# ddr32ss_EMIF_CTLCFG_0F308000h register map
Vendor: Texas Instruments
Registers are 32-bit, read-write, reset 0x0 unless marked. A register's access mark holds for its fields unless they carry their own. Offsets are as the file gives them; [hi:lo] are bit positions; lines under a group give offsets from that group; {n}, {i} and the like mark numbered series.

## emif_ctlcfg (part 6 of 13)
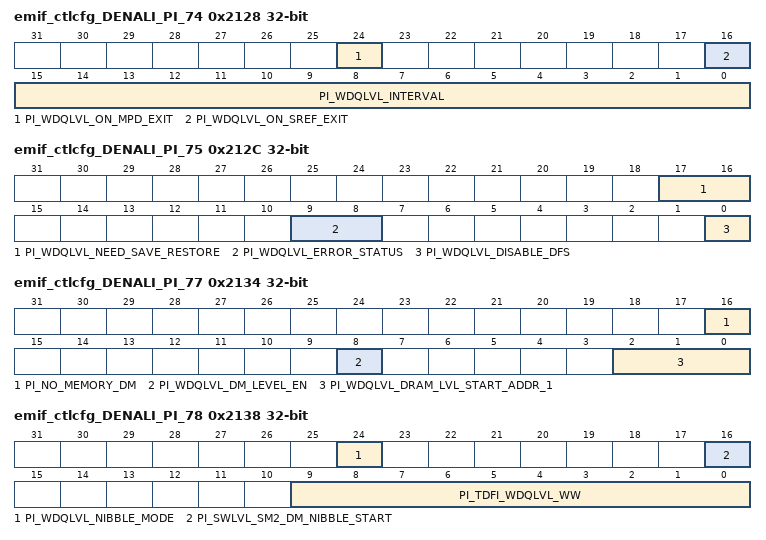
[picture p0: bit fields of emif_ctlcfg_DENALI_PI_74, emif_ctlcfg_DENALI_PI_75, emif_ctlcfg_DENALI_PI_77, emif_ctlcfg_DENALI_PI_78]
0x2128 emif_ctlcfg_DENALI_PI_74
  [24] PI_WDQLVL_ON_MPD_EXIT — Issue a write DQ training command on maximum power saving mode exit. Reset Source: ctl_amod_g_rst_n
  [16] PI_WDQLVL_ON_SREF_EXIT — Issue a write DQ training command on self-refresh exit. Reset Source: ctl_amod_g_rst_n
  [15:0] PI_WDQLVL_INTERVAL — Sets the maximum number of long count sequences allowed between automatic write DQ training operations. Reset Source: ctl_amod_g_rst_n
0x212C emif_ctlcfg_DENALI_PI_75 access per field
  [17:16] PI_WDQLVL_NEED_SAVE_RESTORE rw — Enables the use of functional DRAM address space for write DQ training, 1 = enable, not for LPDDR4. Reset Source: ctl_amod_g_rst_n
  [9:8] PI_WDQLVL_ERROR_STATUS ro — Holds the error associated with the write dq level error interrupt. Bit [0] set indicates a PI_TDFI_WDQLVL_MAX parameter violation and bit [1] set indicates a PI_TDFI_WDQLVL_RESP parameter violation. READ-ONLY. Reset Source: ctl_amod_g_rst_n
  [0] PI_WDQLVL_DISABLE_DFS rw — Disable automatic write DQ training on freq change. Set to 1 to disable. Reset Source: ctl_amod_g_rst_n
0x2130 emif_ctlcfg_DENALI_PI_76
  [31:0] PI_WDQLVL_DRAM_LVL_START_ADDR_0 — Start address of WDQ leveling, not for LPDDR4. Reset Source: ctl_amod_g_rst_n
0x2134 emif_ctlcfg_DENALI_PI_77
  [16] PI_NO_MEMORY_DM — Defines if the attached memory supports the Data Mask function, 1 = not supported. Reset Source: ctl_amod_g_rst_n
  [8] PI_WDQLVL_DM_LEVEL_EN — Enable for write DM training as part of the write DQ training, not for LPDDR4. Reset Source: ctl_amod_g_rst_n
  [2:0] PI_WDQLVL_DRAM_LVL_START_ADDR_1 — Start address of WDQ leveling, not for LPDDR4. Reset Source: ctl_amod_g_rst_n
0x2138 emif_ctlcfg_DENALI_PI_78 access per field
  [24] PI_WDQLVL_NIBBLE_MODE rw — WDQ Training Nibble mode indication. When set to 1, nibble mode is enabled, and the training timing is doubled. Reset Source: ctl_amod_g_rst_n
  [16] PI_SWLVL_SM2_DM_NIBBLE_START wo — Start command for stage 2, when in the process of DM leveling or nibble mode. WRITE-ONLY Reset Source: ctl_amod_g_rst_n
  [9:0] PI_TDFI_WDQLVL_WW rw — Minimum number of DFI clocks to be inserted between write commands during the DM portion of write DQ training. Reset Source: ctl_amod_g_rst_n
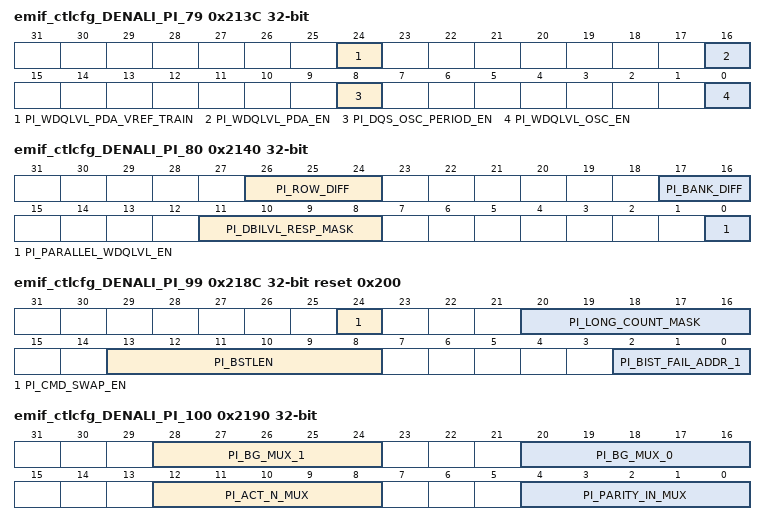
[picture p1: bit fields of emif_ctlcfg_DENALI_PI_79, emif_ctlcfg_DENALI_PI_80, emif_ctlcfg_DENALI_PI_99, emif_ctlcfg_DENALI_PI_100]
0x213C emif_ctlcfg_DENALI_PI_79
  [24] PI_WDQLVL_PDA_VREF_TRAIN — Enable for the use of PDA to set the VREF during write DQ training, 1 = enabled. Reset Source: ctl_amod_g_rst_n
  [16] PI_WDQLVL_PDA_EN — Enable for the use of write DQ training for PDA mode, 1 = enabled. Reset Source: ctl_amod_g_rst_n
  [8] PI_DQS_OSC_PERIOD_EN — Enable for DQS oscillator triggered periodic write DQ training, 1 = enabled. Reset Source: ctl_amod_g_rst_n
  [0] PI_WDQLVL_OSC_EN — Enable for DQS oscillator triggered write DQ training, 1 = enabled. Reset Source: ctl_amod_g_rst_n
0x2140 emif_ctlcfg_DENALI_PI_80
  [26:24] PI_ROW_DIFF — Difference between number of address pins available and number being used. Reset Source: ctl_amod_g_rst_n
  [17:16] PI_BANK_DIFF — Difference between number of bank pins available and number being used. Reset Source: ctl_amod_g_rst_n
  [11:8] PI_DBILVL_RESP_MASK — Mask for the dfi_rdlvl_resp signal during read dbi training. Reset Source: ctl_amod_g_rst_n
  [0] PI_PARALLEL_WDQLVL_EN — Enable per rank parallel Write DQ training for LPDDR4, 1 = enabled. Reset Source: ctl_amod_g_rst_n
0x2144 emif_ctlcfg_DENALI_PI_81
  [4:0] PI_TCCD — DRAM CAS-to-CAS value in cycles. Reset Source: ctl_amod_g_rst_n
{0x2000+4i} emif_ctlcfg_DENALI_PI_{i} access not given reset not defined (i=82..86)
0x215C emif_ctlcfg_DENALI_PI_87 ro
  [29:0] PI_INT_STATUS — Status of interrupt features in the PI. READ-ONLY Reset Source: ctl_amod_g_rst_n
0x2160 emif_ctlcfg_DENALI_PI_88 wo
  [28:0] PI_INT_ACK — Clear the corresponding interrupt bit of the PI_INT_STATUS parameter. WRITE-ONLY Reset Source: ctl_amod_g_rst_n
0x2164 emif_ctlcfg_DENALI_PI_89
  [29:0] PI_INT_MASK — Mask for PI_int signals from the PI_INT_STATUS parameter. Reset Source: ctl_amod_g_rst_n
{0x2000+4i} emif_ctlcfg_DENALI_PI_{i} ro (i=90..93)
  [31:0] PI_BIST_EXP_DATA_{i-90} — Expected data on BIST error. READ-ONLY Reset Source: ctl_amod_g_rst_n
{0x2000+4i} emif_ctlcfg_DENALI_PI_{i} ro (i=94..97)
  [31:0] PI_BIST_FAIL_DATA_{i-94} — Actual data on BIST error. READ-ONLY Reset Source: ctl_amod_g_rst_n
0x2188 emif_ctlcfg_DENALI_PI_98 ro
  [31:0] PI_BIST_FAIL_ADDR_0 — The burst aligned address of BIST error. READ-ONLY Reset Source: ctl_amod_g_rst_n
0x218C emif_ctlcfg_DENALI_PI_99 access per field reset 0x200
  [24] PI_CMD_SWAP_EN rw — Command pin swap function enable Reset Source: ctl_amod_g_rst_n
  [20:16] PI_LONG_COUNT_MASK rw — Reduces the length of the long counter from 1024 cycles. Reset Source: ctl_amod_g_rst_n
  [13:8] PI_BSTLEN rw — Encoded burst length sent to DRAMs during initialization. Reset Source: ctl_amod_g_rst_n
  [2:0] PI_BIST_FAIL_ADDR_1 ro — The burst aligned address of BIST error. READ-ONLY Reset Source: ctl_amod_g_rst_n
0x2190 emif_ctlcfg_DENALI_PI_100
  [28:24] PI_BG_MUX_1 — Command pin BG_1 mux selector Reset Source: ctl_amod_g_rst_n
  [20:16] PI_BG_MUX_0 — Command pin BG_0 mux selector Reset Source: ctl_amod_g_rst_n
  [12:8] PI_ACT_N_MUX — Command pin ACT_N mux selector Reset Source: ctl_amod_g_rst_n
  [4:0] PI_PARITY_IN_MUX — Command pin parity mux selector Reset Source: ctl_amod_g_rst_n
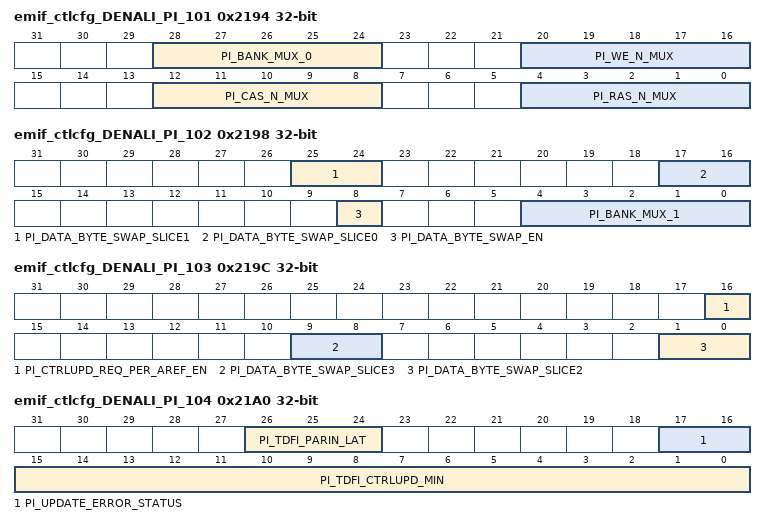
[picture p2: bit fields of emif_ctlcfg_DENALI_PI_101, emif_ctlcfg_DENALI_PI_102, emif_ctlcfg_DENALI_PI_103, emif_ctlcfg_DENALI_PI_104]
0x2194 emif_ctlcfg_DENALI_PI_101
  [28:24] PI_BANK_MUX_0 — Command pin BANK_0 mux selector Reset Source: ctl_amod_g_rst_n
  [20:16] PI_WE_N_MUX — Command pin WE_N mux selector Reset Source: ctl_amod_g_rst_n
  [12:8] PI_CAS_N_MUX — Command pin CAS_N mux selector Reset Source: ctl_amod_g_rst_n
  [4:0] PI_RAS_N_MUX — Command pin RAS_N mux selector Reset Source: ctl_amod_g_rst_n
0x2198 emif_ctlcfg_DENALI_PI_102
  [25:24] PI_DATA_BYTE_SWAP_SLICE1 — DATA pin 1 mux selector Reset Source: ctl_amod_g_rst_n
  [17:16] PI_DATA_BYTE_SWAP_SLICE0 — DATA pin 0 mux selector Reset Source: ctl_amod_g_rst_n
  [8] PI_DATA_BYTE_SWAP_EN — DATA pin swap function enable Reset Source: ctl_amod_g_rst_n
  [4:0] PI_BANK_MUX_1 — Command pin BANK_1 mux selector Reset Source: ctl_amod_g_rst_n
0x219C emif_ctlcfg_DENALI_PI_103
  [16] PI_CTRLUPD_REQ_PER_AREF_EN — Enable an automatic PI initiated update [dfi_ctrlupd_req] after every refresh. Set to 1 to enable. Reset Source: ctl_amod_g_rst_n
  [9:8] PI_DATA_BYTE_SWAP_SLICE3 — DATA pin 3 mux selector Reset Source: ctl_amod_g_rst_n
  [1:0] PI_DATA_BYTE_SWAP_SLICE2 — DATA pin 2 mux selector Reset Source: ctl_amod_g_rst_n
0x21A0 emif_ctlcfg_DENALI_PI_104 access per field
  [26:24] PI_TDFI_PARIN_LAT rw — Defines the DFI tPARIN_LAT timing parameter [in DFI PHY clocks], the maximum cycles between a DFI command and a dfi_parity_in signal assertion. Reset Source: ctl_amod_g_rst_n
  [17:16] PI_UPDATE_ERROR_STATUS ro — Identifies the source of any DFI PI-initiated update errors. Value of 1 indicates a timing violation of the associated timing parameter. Bit 1-0: ctrlupd_max_error, ctrlupd_interval_error. Bit 6-2: reserved. READ-ONLY Reset Source: ctl_amod_g_rst_n
  [15:0] PI_TDFI_CTRLUPD_MIN rw — Reports the DFI tCTRLUPD_MIN timing parameter [in DFI clocks], the minimum cycles that dfi_ctrlupd_req must be asserted. Reset Source: ctl_amod_g_rst_n
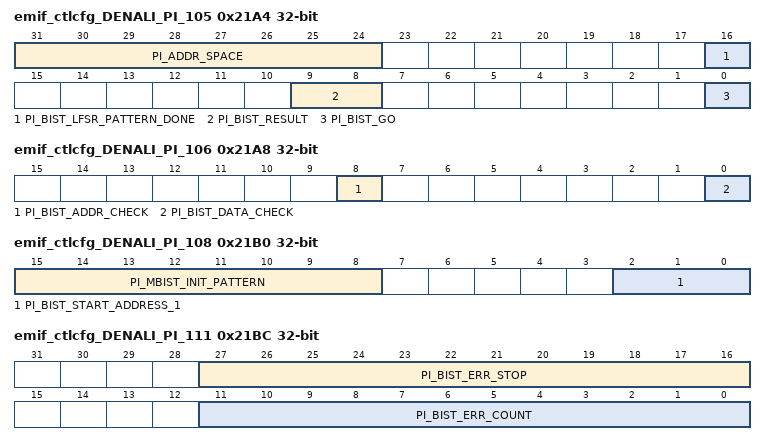
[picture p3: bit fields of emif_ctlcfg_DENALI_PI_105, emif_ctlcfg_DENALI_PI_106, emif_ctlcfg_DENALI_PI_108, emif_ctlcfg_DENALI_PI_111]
0x21A4 emif_ctlcfg_DENALI_PI_105 access per field
  [31:24] PI_ADDR_SPACE rw — Sets the number of address bits to check during BIST operation. The end address of BIST is start_address+[1 shifted up by PI_ADDR_SPACE]-1. The end address should not beyond the actual memory address range. Reset Source: ctl_amod_g_rst_n
  [16] PI_BIST_LFSR_PATTERN_DONE ro — BIST operation lfsr pattern, data pattern 1'b0 means the data is useful,1'b1 means next pattern sequence can ingore. READ-ONLY Reset Source: ctl_amod_g_rst_n
  [9:8] PI_BIST_RESULT ro — BIST operation status [pass/fail]. Bit [0] indicates data check status and bit [1] indicates address check status. Value of 1 is a passing result. READ-ONLY Reset Source: ctl_amod_g_rst_n
  [0] PI_BIST_GO rw — Initiate a BIST operation. Set to 1 to trigger. Reset Source: ctl_amod_g_rst_n
0x21A8 emif_ctlcfg_DENALI_PI_106
  [8] PI_BIST_ADDR_CHECK — Enable address checking with BIST operation. Set to 1 to enable. Reset Source: ctl_amod_g_rst_n
  [0] PI_BIST_DATA_CHECK — Enable data checking with BIST operation. Set to 1 to enable. Reset Source: ctl_amod_g_rst_n
0x21AC emif_ctlcfg_DENALI_PI_107
  [31:0] PI_BIST_START_ADDRESS_0 — Start BIST checking at this address. Reset Source: ctl_amod_g_rst_n
0x21B0 emif_ctlcfg_DENALI_PI_108
  [15:8] PI_MBIST_INIT_PATTERN — PI mbist data check, random lfsr pattern mode init pattern seed. Reset Source: ctl_amod_g_rst_n
  [2:0] PI_BIST_START_ADDRESS_1 — Start BIST checking at this address. Reset Source: ctl_amod_g_rst_n
0x21B4 emif_ctlcfg_DENALI_PI_109
  [31:0] PI_BIST_DATA_MASK_0 — Mask applied to data for BIST error checking. Bit [0] controls memory data path bit [0], bit [1] controls memory data path bit [1], etc. The mask range is the data transfer size in each memory clock cycle [The data on a rising edge and a failing edge]. Set each bit to 1 to mask. Reset Source: ctl_amod_g_rst_n
0x21B8 emif_ctlcfg_DENALI_PI_110
  [31:0] PI_BIST_DATA_MASK_1 — Mask applied to data for BIST error checking. Bit [0] controls memory data path bit [0], bit [1] controls memory data path bit [1], etc. The mask range is the data transfer size in each memory clock cycle [The data on a rising edge and a failing edge]. Set each bit to 1 to mask. Reset Source: ctl_amod_g_rst_n
0x21BC emif_ctlcfg_DENALI_PI_111 access per field
  [27:16] PI_BIST_ERR_STOP rw — Defines the maximum number of error occurrences allowed prior to quitting when the BIST_TEST_MODE parameter is set to 1, 2 or 3. A value of 0 will allow the test to run to completion. Reset Source: ctl_amod_g_rst_n
  [11:0] PI_BIST_ERR_COUNT ro — Indicates the number of BIST errors found when the BIST_TEST_MODE parameter is set to 1, 2 or 3. READ-ONLY Reset Source: ctl_amod_g_rst_n
0x21C0 emif_ctlcfg_DENALI_PI_112
  [31:0] PI_BIST_ADDR_MASK_0_0 — Defines an address to be masked during the BIST operation.. Reset Source: ctl_amod_g_rst_n
0x21C4 emif_ctlcfg_DENALI_PI_113
  [3:0] PI_BIST_ADDR_MASK_0_1 — Defines an address to be masked during the BIST operation.. Reset Source: ctl_amod_g_rst_n
0x21C8 emif_ctlcfg_DENALI_PI_114
  [31:0] PI_BIST_ADDR_MASK_1_0 — Defines an address to be masked during the BIST operation.. Reset Source: ctl_amod_g_rst_n
0x21CC emif_ctlcfg_DENALI_PI_115
  [3:0] PI_BIST_ADDR_MASK_1_1 — Defines an address to be masked during the BIST operation.. Reset Source: ctl_amod_g_rst_n
0x21D0 emif_ctlcfg_DENALI_PI_116
  [31:0] PI_BIST_ADDR_MASK_2_0 — Defines an address to be masked during the BIST operation.. Reset Source: ctl_amod_g_rst_n
0x21D4 emif_ctlcfg_DENALI_PI_117
  [3:0] PI_BIST_ADDR_MASK_2_1 — Defines an address to be masked during the BIST operation.. Reset Source: ctl_amod_g_rst_n
0x21D8 emif_ctlcfg_DENALI_PI_118
  [31:0] PI_BIST_ADDR_MASK_3_0 — Defines an address to be masked during the BIST operation.. Reset Source: ctl_amod_g_rst_n
0x21DC emif_ctlcfg_DENALI_PI_119
  [3:0] PI_BIST_ADDR_MASK_3_1 — Defines an address to be masked during the BIST operation.. Reset Source: ctl_amod_g_rst_n
0x21E0 emif_ctlcfg_DENALI_PI_120
  [31:0] PI_BIST_ADDR_MASK_4_0 — Defines an address to be masked during the BIST operation.. Reset Source: ctl_amod_g_rst_n
0x21E4 emif_ctlcfg_DENALI_PI_121
  [3:0] PI_BIST_ADDR_MASK_4_1 — Defines an address to be masked during the BIST operation.. Reset Source: ctl_amod_g_rst_n
0x21E8 emif_ctlcfg_DENALI_PI_122
  [31:0] PI_BIST_ADDR_MASK_5_0 — Defines an address to be masked during the BIST operation.. Reset Source: ctl_amod_g_rst_n
0x21EC emif_ctlcfg_DENALI_PI_123
  [3:0] PI_BIST_ADDR_MASK_5_1 — Defines an address to be masked during the BIST operation.. Reset Source: ctl_amod_g_rst_n
0x21F0 emif_ctlcfg_DENALI_PI_124
  [31:0] PI_BIST_ADDR_MASK_6_0 — Defines an address to be masked during the BIST operation.. Reset Source: ctl_amod_g_rst_n
0x21F4 emif_ctlcfg_DENALI_PI_125
  [3:0] PI_BIST_ADDR_MASK_6_1 — Defines an address to be masked during the BIST operation.. Reset Source: ctl_amod_g_rst_n
0x21F8 emif_ctlcfg_DENALI_PI_126
  [31:0] PI_BIST_ADDR_MASK_7_0 — Defines an address to be masked during the BIST operation.. Reset Source: ctl_amod_g_rst_n
0x21FC emif_ctlcfg_DENALI_PI_127
  [3:0] PI_BIST_ADDR_MASK_7_1 — Defines an address to be masked during the BIST operation.. Reset Source: ctl_amod_g_rst_n
0x2200 emif_ctlcfg_DENALI_PI_128
  [31:0] PI_BIST_ADDR_MASK_8_0 — Defines an address to be masked during the BIST operation.. Reset Source: ctl_amod_g_rst_n
0x2204 emif_ctlcfg_DENALI_PI_129
  [3:0] PI_BIST_ADDR_MASK_8_1 — Defines an address to be masked during the BIST operation.. Reset Source: ctl_amod_g_rst_n
0x2208 emif_ctlcfg_DENALI_PI_130
  [31:0] PI_BIST_ADDR_MASK_9_0 — Defines an address to be masked during the BIST operation.. Reset Source: ctl_amod_g_rst_n
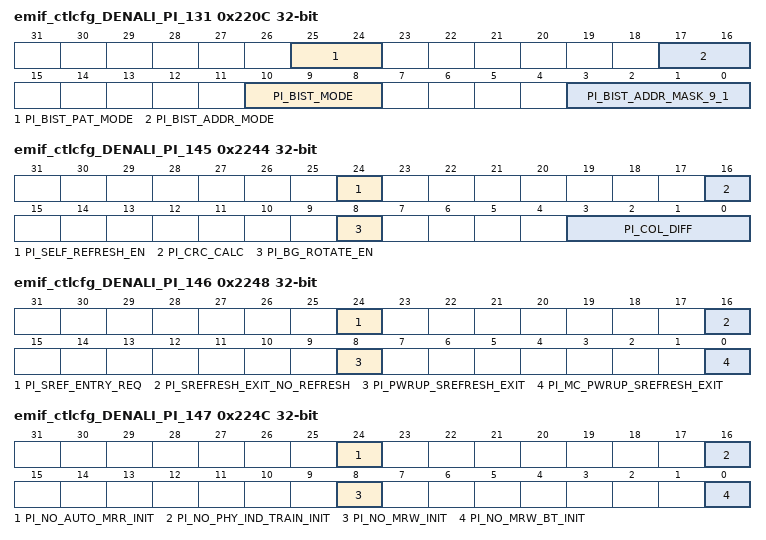
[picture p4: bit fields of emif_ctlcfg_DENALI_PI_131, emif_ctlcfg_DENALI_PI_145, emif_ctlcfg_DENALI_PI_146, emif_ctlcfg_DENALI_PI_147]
0x220C emif_ctlcfg_DENALI_PI_131
  [25:24] PI_BIST_PAT_MODE — Sets the pattern mode of BIST. 'b00 indicates using built-in pattern. 'b01 indicates checkerboard pattern, each data transfer inverts the last data transfer based on the built-in pattern. 'b10 indicates using both user pattern and built-in pattern. 'b11 indicates using pi lfsr random pattern. Reset Source: ctl_amod_g_rst_n
  [17:16] PI_BIST_ADDR_MODE — Sets the address traversing order of BIST. 'b00 indicates fast column order [burst-column-bank-row-rank]. 'b01 indicates fast row order [burst-row-column-bank-rank]. 'b10 indicates fast bank order [burst-bank-column-row-rank]. Reset Source: ctl_amod_g_rst_n
  [10:8] PI_BIST_MODE — Sets the BIST data checking mode. 'b00 indicates MOVI13N mode. 'b01 indicates March C mode. 'b10 indicates GALPAT mode. 'b11 indicates PRBS mode. 'b100 indicates programmable March data check mode. Reset Source: ctl_amod_g_rst_n
  [3:0] PI_BIST_ADDR_MASK_9_1 — Defines an address to be masked during the BIST operation.. Reset Source: ctl_amod_g_rst_n
{0x2000+4i} emif_ctlcfg_DENALI_PI_{i} (i=132..135)
  [31:0] PI_BIST_USER_PAT_{i-132} — Sets the user-specified pattern of BIST. Reset Source: ctl_amod_g_rst_n
0x2220 emif_ctlcfg_DENALI_PI_136
  [6:0] PI_BIST_PAT_NUM — Sets the max used pattern number of BIST from a total of 8 built-in patterns. Ex. set to 3, The BIST would use pattern 1, 2 and 3. Reset Source: ctl_amod_g_rst_n
{0x2000+4i} emif_ctlcfg_DENALI_PI_{i} (i=137..144)
  [29:0] PI_BIST_STAGE_{i-137} — Sets the programmable algorithm of each stage X when pi_bist_mmode = 'h4. Reset Source: ctl_amod_g_rst_n
0x2244 emif_ctlcfg_DENALI_PI_145
  [24] PI_SELF_REFRESH_EN — Control for PI to enable self refresh mode. Set to 1 to enable. Reset Source: ctl_amod_g_rst_n
  [16] PI_CRC_CALC — Defines where CRC is performed; set to 1 for PI responsibility or clear to 0 for PHY responsibility. Reset Source: ctl_amod_g_rst_n
  [8] PI_BG_ROTATE_EN — Enable bank group rotation. Set to 1 to enable. Reset Source: ctl_amod_g_rst_n
  [3:0] PI_COL_DIFF — Difference between number of column pins available and number being used. Reset Source: ctl_amod_g_rst_n
0x2248 emif_ctlcfg_DENALI_PI_146 access per field
  [24] PI_SREF_ENTRY_REQ wo — In PI power up data retention, PI can issued sref entry command. WRITE-ONLY Reset Source: ctl_amod_g_rst_n
  [16] PI_SREFRESH_EXIT_NO_REFRESH rw — Disables the automatic refresh request associated with self-refresh exit. Set to 1 to disable. Reset Source: ctl_amod_g_rst_n
  [8] PI_PWRUP_SREFRESH_EXIT rw — PI control powerup via self-refresh instead of full memory initialization. Set to 1 to enable. Reset Source: ctl_amod_g_rst_n
  [0] PI_MC_PWRUP_SREFRESH_EXIT rw — It indicates MC control powerup via self-refresh instead of full memory initialization. Set to 1 to enable. Reset Source: ctl_amod_g_rst_n
0x224C emif_ctlcfg_DENALI_PI_147
  [24] PI_NO_AUTO_MRR_INIT — Disable MRR commands during initialization. Set to 1 to disable. Reset Source: ctl_amod_g_rst_n
  [16] PI_NO_PHY_IND_TRAIN_INIT — Disable PHY Independent Training during initialization. Set to 1 to disable. Reset Source: ctl_amod_g_rst_n
  [8] PI_NO_MRW_INIT — Disable MRW commands after training during initialization. Set to 1 to disable. Reset Source: ctl_amod_g_rst_n
  [0] PI_NO_MRW_BT_INIT — Disable MRW commands before training during initialization. Set to 1 to disable. Reset Source: ctl_amod_g_rst_n
0x2250 emif_ctlcfg_DENALI_PI_148
  [31:0] PI_TRST_PWRON — Duration of memory reset during power-on initialization. Reset Source: ctl_amod_g_rst_n
0x2254 emif_ctlcfg_DENALI_PI_149
  [31:0] PI_CKE_INACTIVE — Number of cycles after reset before CKE will be active. Reset Source: ctl_amod_g_rst_n
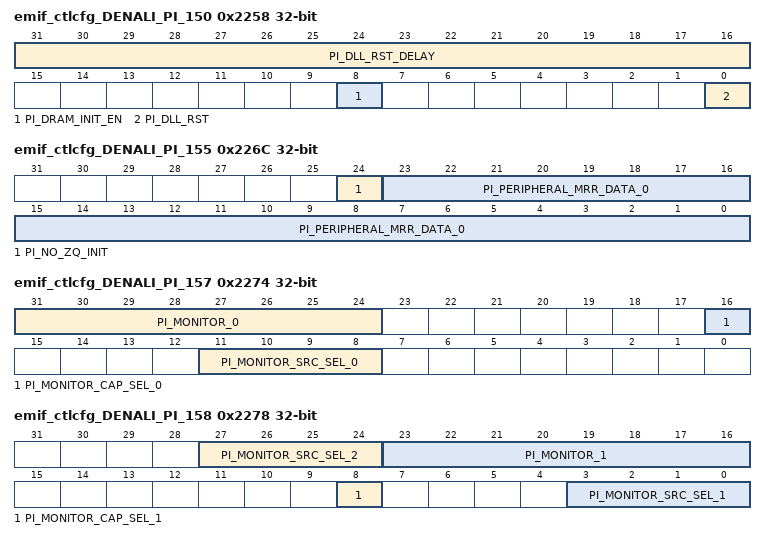
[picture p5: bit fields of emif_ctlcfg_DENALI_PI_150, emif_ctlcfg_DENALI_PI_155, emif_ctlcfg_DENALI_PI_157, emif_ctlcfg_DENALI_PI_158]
0x2258 emif_ctlcfg_DENALI_PI_150
  [31:16] PI_DLL_RST_DELAY — Minimum cycles required for DLL reset signal dll_rst_n to be held. Reset Source: ctl_amod_g_rst_n
  [8] PI_DRAM_INIT_EN — Control for the initialization of DRAM by the PI. Reset Source: ctl_amod_g_rst_n
  [0] PI_DLL_RST — Enables use of the DLL reset [dll_rst_n]. Reset Source: ctl_amod_g_rst_n
0x225C emif_ctlcfg_DENALI_PI_151
  [7:0] PI_DLL_RST_ADJ_DLY — Minimum cycles after setting master delay in DLL until the DLL reset signal dll_rst_n may be asserted. Reset Source: ctl_amod_g_rst_n
0x2260 emif_ctlcfg_DENALI_PI_152
  [25:0] PI_WRITE_MODEREG — Write memory mode register data to the DRAMs. Bits [7:0] define the memory mode register number if bit [23] is set, bits [15:8] define the chip select if bit [24] is clear, bits [23:16] define which memory mode register/s to write, bit [24] defines whether all chip selects will be written, and bit [25] triggers the write. Reset Source: ctl_amod_g_rst_n
0x2264 emif_ctlcfg_DENALI_PI_153 ro
  [7:0] PI_MRW_STATUS — Write memory mode register status. Bit [0] set indicates a WRITE_MODEREG parameter programming error. Bit [1] set indicates a PASR error. Bit [2] is Reserved. Bit [3] set indicates a self refresh or deep power down error. Bit [4] set indicates that a write to MR3 or MR11 was attempted [write_modereg bit [25] was asserted with bit [17] set, or bit [23] was asserted with bits [7:0] defining MR3 or MR11] during tZQCAL after a ZQ calibration start command. READ-ONLY Reset Source: ctl_amod_g_rst_n
0x2268 emif_ctlcfg_DENALI_PI_154
  [16:0] PI_READ_MODEREG — Read the specified memory mode register from specified chip when start bit set. Bits [7:0] define the memory mode register and bits [15:8] define the chip select. Set bit [16] to 1 to trigger. Reset Source: ctl_amod_g_rst_n
0x226C emif_ctlcfg_DENALI_PI_155 access per field
  [24] PI_NO_ZQ_INIT rw — Disable ZQ operations during initialization. Set to 1 to disable. Reset Source: ctl_amod_g_rst_n
  [23:0] PI_PERIPHERAL_MRR_DATA_0 ro — Data and chip returned from memory mode register read requested by the READ_MODEREG parameter, Bits [15:0] define MRR data, [23:16] define the chip select. READ-ONLY Reset Source: ctl_amod_g_rst_n
0x2270 emif_ctlcfg_DENALI_PI_156 ro
  [16] PI_ZQ_REQ_PENDING — Indicates that a ZQ command is currently in progress or waiting to run. When this is asserted, no writes to ZQ_REQ should occur. READ-ONLY Reset Source: ctl_amod_g_rst_n
0x2274 emif_ctlcfg_DENALI_PI_157 access per field
  [31:24] PI_MONITOR_0 ro — Monitor register 0. READ-ONLY. Reset Source: ctl_amod_g_rst_n
  [16] PI_MONITOR_CAP_SEL_0 rw — Selection of captures for pi_monitor_0. Reset Source: ctl_amod_g_rst_n
  [11:8] PI_MONITOR_SRC_SEL_0 rw — Selection of sources for pi_monitor_0. Reset Source: ctl_amod_g_rst_n
0x2278 emif_ctlcfg_DENALI_PI_158 access per field
  [27:24] PI_MONITOR_SRC_SEL_2 rw — Selection of sources for pi_monitor_2. Reset Source: ctl_amod_g_rst_n
  [23:16] PI_MONITOR_1 ro — Monitor register 1. READ-ONLY. Reset Source: ctl_amod_g_rst_n
  [8] PI_MONITOR_CAP_SEL_1 rw — Selection of captures for pi_monitor_1. Reset Source: ctl_amod_g_rst_n
  [3:0] PI_MONITOR_SRC_SEL_1 rw — Selection of sources for pi_monitor_1. Reset Source: ctl_amod_g_rst_n
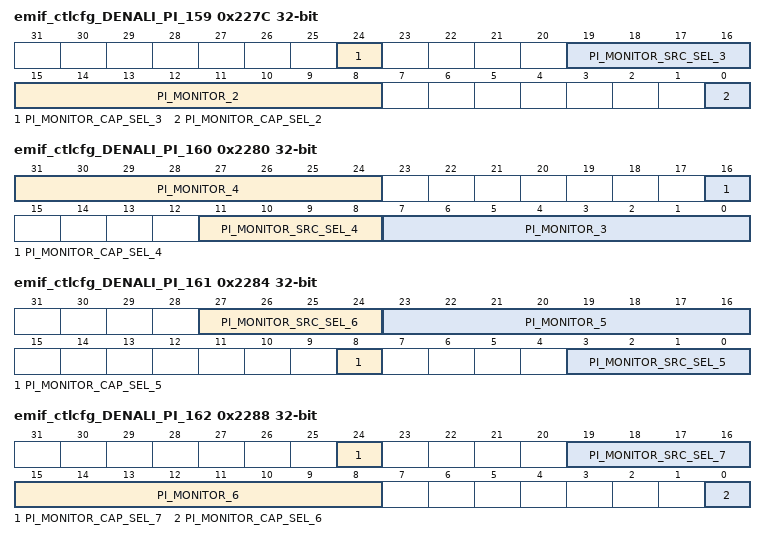
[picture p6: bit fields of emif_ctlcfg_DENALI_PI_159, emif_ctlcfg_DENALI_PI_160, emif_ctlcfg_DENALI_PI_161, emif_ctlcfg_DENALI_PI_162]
0x227C emif_ctlcfg_DENALI_PI_159 access per field
  [24] PI_MONITOR_CAP_SEL_3 rw — Selection of captures for pi_monitor_3. Reset Source: ctl_amod_g_rst_n
  [19:16] PI_MONITOR_SRC_SEL_3 rw — Selection of sources for pi_monitor_3. Reset Source: ctl_amod_g_rst_n
  [15:8] PI_MONITOR_2 ro — Monitor register 2. READ-ONLY. Reset Source: ctl_amod_g_rst_n
  [0] PI_MONITOR_CAP_SEL_2 rw — Selection of captures for pi_monitor_2. Reset Source: ctl_amod_g_rst_n
0x2280 emif_ctlcfg_DENALI_PI_160 access per field
  [31:24] PI_MONITOR_4 ro — Monitor register 4. READ-ONLY. Reset Source: ctl_amod_g_rst_n
  [16] PI_MONITOR_CAP_SEL_4 rw — Selection of captures for pi_monitor_4. Reset Source: ctl_amod_g_rst_n
  [11:8] PI_MONITOR_SRC_SEL_4 rw — Selection of sources for pi_monitor_4. Reset Source: ctl_amod_g_rst_n
  [7:0] PI_MONITOR_3 ro — Monitor register 3. READ-ONLY. Reset Source: ctl_amod_g_rst_n
0x2284 emif_ctlcfg_DENALI_PI_161 access per field
  [27:24] PI_MONITOR_SRC_SEL_6 rw — Selection of sources for pi_monitor_6. Reset Source: ctl_amod_g_rst_n
  [23:16] PI_MONITOR_5 ro — Monitor register 5. READ-ONLY. Reset Source: ctl_amod_g_rst_n
  [8] PI_MONITOR_CAP_SEL_5 rw — Selection of captures for pi_monitor_5. Reset Source: ctl_amod_g_rst_n
  [3:0] PI_MONITOR_SRC_SEL_5 rw — Selection of sources for pi_monitor_5. Reset Source: ctl_amod_g_rst_n
0x2288 emif_ctlcfg_DENALI_PI_162 access per field
  [24] PI_MONITOR_CAP_SEL_7 rw — Selection of captures for pi_monitor_7. Reset Source: ctl_amod_g_rst_n
  [19:16] PI_MONITOR_SRC_SEL_7 rw — Selection of sources for pi_monitor_7. Reset Source: ctl_amod_g_rst_n
  [15:8] PI_MONITOR_6 ro — Monitor register 6. READ-ONLY. Reset Source: ctl_amod_g_rst_n
  [0] PI_MONITOR_CAP_SEL_6 rw — Selection of captures for pi_monitor_6. Reset Source: ctl_amod_g_rst_n
0x228C emif_ctlcfg_DENALI_PI_163 ro
  [7:0] PI_MONITOR_7 — Monitor register 7. READ-ONLY. Reset Source: ctl_amod_g_rst_n
0x2290 emif_ctlcfg_DENALI_PI_164 wo
  [7:0] PI_MONITOR_STROBE — Strobe the pi_monitor once. Every bit corresponds respectively with a pi_monitor. WRITE-ONLY Reset Source: ctl_amod_g_rst_n
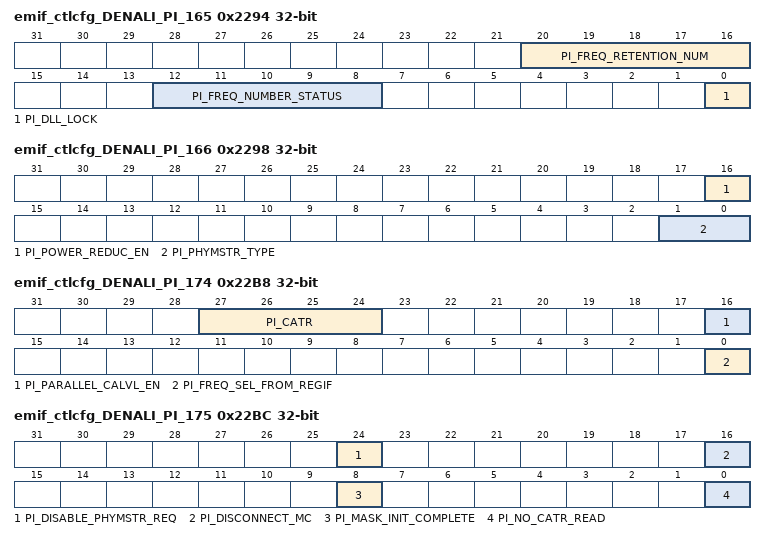
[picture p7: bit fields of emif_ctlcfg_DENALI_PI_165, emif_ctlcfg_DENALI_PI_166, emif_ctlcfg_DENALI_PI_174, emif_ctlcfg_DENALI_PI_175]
0x2294 emif_ctlcfg_DENALI_PI_165 access per field
  [20:16] PI_FREQ_RETENTION_NUM rw — Monitor active freq number in PI for data_retention Reset Source: ctl_amod_g_rst_n
  [12:8] PI_FREQ_NUMBER_STATUS ro — Monitor active freq number in PI. READ-ONLY. Reset Source: ctl_amod_g_rst_n
  [0] PI_DLL_LOCK ro — Monitor dfi_init_complete from PHY. READ-ONLY. Reset Source: ctl_amod_g_rst_n
0x2298 emif_ctlcfg_DENALI_PI_166
  [16] PI_POWER_REDUC_EN — PI Power reduction enable, 1 = enabled. Reset Source: ctl_amod_g_rst_n
  [1:0] PI_PHYMSTR_TYPE — Defines how the controller should set the state of DRAM before turning control of the DFI bus over to the PI. Reset Source: ctl_amod_g_rst_n
{0x2000+4i} emif_ctlcfg_DENALI_PI_{i} access not given reset not defined (i=167..170)
0x22AC emif_ctlcfg_DENALI_PI_171
  [23:16] PI_WRLVL_MAX_STROBE_PEND — Defines the maximum number of wrlvl_strobes that be accumulated before an AREF is prevented from being generated. Reset Source: ctl_amod_g_rst_n
0x22B0 emif_ctlcfg_DENALI_PI_172
  [8:0] PI_TREFBW_THR — Threshold value to control the AREF command interval. When the number of pending AREF is over this value, the interval is expanded to be tREF/8. Reset Source: ctl_amod_g_rst_n
0x22B4 emif_ctlcfg_DENALI_PI_173
  [4:0] PI_FREQ_CHANGE_REG_COPY — In non-DFI 4.0 mode, contains the frequency copy value. Reset Source: ctl_amod_g_rst_n
0x22B8 emif_ctlcfg_DENALI_PI_174
  [27:24] PI_CATR — It indicates LP4 DRAM CA terminition ON/OFF state. Each bit corresponds to each chip select. 1:ON 0:OFF. This parameter is active when PI_NO_CATR_READ==1. When PI_NO_CATR_READ==0, this param is inactive Reset Source: ctl_amod_g_rst_n
  [16] PI_PARALLEL_CALVL_EN — Enable parallel channel CA training for LPDDR4. 1: All the channels in one rank do CA Training in parallel. 0: Each channel does CA Training in sequence Reset Source: ctl_amod_g_rst_n
  [0] PI_FREQ_SEL_FROM_REGIF — In non-DFI 4.0 mode, user select the frequency copies from pi_freq_change_reg_copy. Reset Source: ctl_amod_g_rst_n
0x22BC emif_ctlcfg_DENALI_PI_175
  [24] PI_DISABLE_PHYMSTR_REQ — PI mask dfi_phymstr_req to the controller and get dfi bus without dfi_phymstr_ack, 1: disconnect Reset Source: ctl_amod_g_rst_n
  [16] PI_DISCONNECT_MC — PI disconnects the controller from the PHY, 1: disconnect Reset Source: ctl_amod_g_rst_n
  [8] PI_MASK_INIT_COMPLETE — Enable the masking of the dfi_init_complete signal back to the controller, 1: mask. Reset Source: ctl_amod_g_rst_n
  [0] PI_NO_CATR_READ — Defines how the LPDDR4 termination status is determined. 1: PI use PI_CATR to get DRAM CA Termination status. 0: PI reads DRAM MR0.OP7 to get DRAM CA Termination status. Reset Source: ctl_amod_g_rst_n
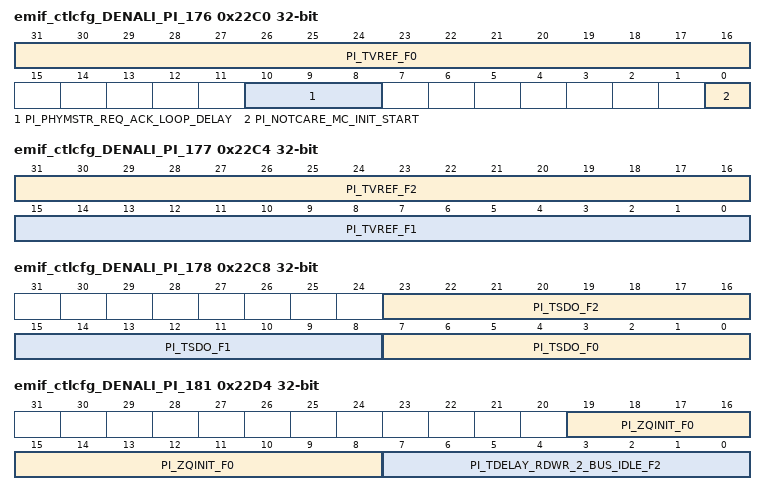
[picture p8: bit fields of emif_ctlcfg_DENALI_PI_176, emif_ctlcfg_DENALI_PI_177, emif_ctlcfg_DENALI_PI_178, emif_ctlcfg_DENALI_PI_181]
0x22C0 emif_ctlcfg_DENALI_PI_176
  [31:16] PI_TVREF_F0 — Defines the number of cycles that the PI should wait before issuing the next command after a VREF training MRW command for frequency set 0. Reset Source: ctl_amod_g_rst_n
  [10:8] PI_PHYMSTR_REQ_ACK_LOOP_DELAY — The delay between phymstr_req and inner phymstr_ack when PI_DISABLE_PHYMSTR_REQ set 1 Reset Source: ctl_amod_g_rst_n
  [0] PI_NOTCARE_MC_INIT_START — Defines whether PI waits for the controller to initiate dfi_init_start before PI memory initialization, 1: wait for dfi_init_start Reset Source: ctl_amod_g_rst_n
0x22C4 emif_ctlcfg_DENALI_PI_177
  [31:16] PI_TVREF_F2 — Defines the number of cycles that the PI should wait before issuing the next command after a VREF training MRW command for frequency set 2. Reset Source: ctl_amod_g_rst_n
  [15:0] PI_TVREF_F1 — Defines the number of cycles that the PI should wait before issuing the next command after a VREF training MRW command for frequency set 1. Reset Source: ctl_amod_g_rst_n
0x22C8 emif_ctlcfg_DENALI_PI_178
  [23:16] PI_TSDO_F2 — The delay from the read preamble training MRS command to the data strobe drive out for frequency set 2, in PI clocks Reset Source: ctl_amod_g_rst_n
  [15:8] PI_TSDO_F1 — The delay from the read preamble training MRS command to the data strobe drive out for frequency set 1, in PI clocks Reset Source: ctl_amod_g_rst_n
  [7:0] PI_TSDO_F0 — The delay from the read preamble training MRS command to the data strobe drive out for frequency set 0, in PI clocks Reset Source: ctl_amod_g_rst_n
0x22CC emif_ctlcfg_DENALI_PI_179
  [7:0] PI_TDELAY_RDWR_2_BUS_IDLE_F0 — The delay from read or write to bus idle for frequency set 0. Recommend setting is: delay time from read command issued to last read data received. Reset Source: ctl_amod_g_rst_n
0x22D0 emif_ctlcfg_DENALI_PI_180
  [7:0] PI_TDELAY_RDWR_2_BUS_IDLE_F1 — The delay from read or write to bus idle for frequency set 1. Recommend setting is: delay time from read command issued to last read data received. Reset Source: ctl_amod_g_rst_n
0x22D4 emif_ctlcfg_DENALI_PI_181
  [19:8] PI_ZQINIT_F0 — Number of cycles needed for a ZQINIT command for frequency set 0. Reset Source: ctl_amod_g_rst_n
  [7:0] PI_TDELAY_RDWR_2_BUS_IDLE_F2 — The delay from read or write to bus idle for frequency set 2. Recommend setting is: delay time from read command issued to last read data received. Reset Source: ctl_amod_g_rst_n
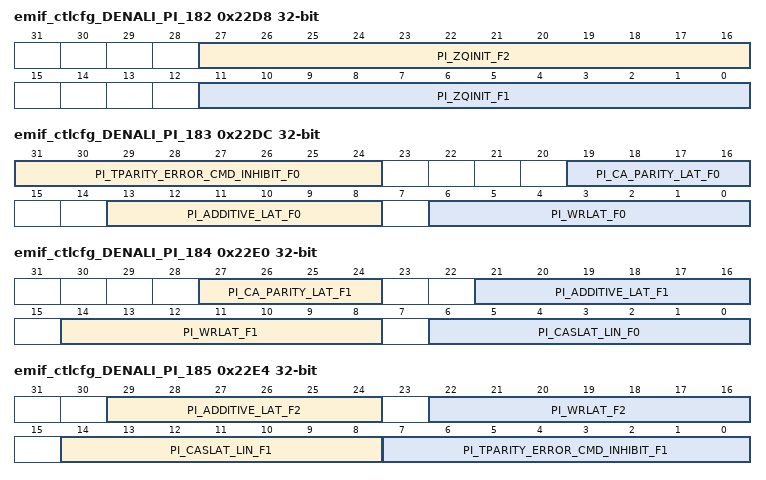
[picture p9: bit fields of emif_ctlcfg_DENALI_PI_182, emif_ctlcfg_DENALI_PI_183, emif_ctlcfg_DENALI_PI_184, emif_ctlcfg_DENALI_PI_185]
0x22D8 emif_ctlcfg_DENALI_PI_182
  [27:16] PI_ZQINIT_F2 — Number of cycles needed for a ZQINIT command for frequency set 2. Reset Source: ctl_amod_g_rst_n
  [11:0] PI_ZQINIT_F1 — Number of cycles needed for a ZQINIT command for frequency set 1. Reset Source: ctl_amod_g_rst_n
0x22DC emif_ctlcfg_DENALI_PI_183
  [31:24] PI_TPARITY_ERROR_CMD_INHIBIT_F0 — Defines the window after the PI receives a parity error during which DRAM commands will not execute for frequency set 0. Reset Source: ctl_amod_g_rst_n
  [19:16] PI_CA_PARITY_LAT_F0 — DRAM CA parity latency value in cycles for frequency set 0. Reset Source: ctl_amod_g_rst_n
  [13:8] PI_ADDITIVE_LAT_F0 — DRAM additive latency value in cycles for frequency set 0. Reset Source: ctl_amod_g_rst_n
  [6:0] PI_WRLAT_F0 — DRAM WRLAT value in cycles for frequency set 0. Reset Source: ctl_amod_g_rst_n
0x22E0 emif_ctlcfg_DENALI_PI_184
  [27:24] PI_CA_PARITY_LAT_F1 — DRAM CA parity latency value in cycles for frequency set 1. Reset Source: ctl_amod_g_rst_n
  [21:16] PI_ADDITIVE_LAT_F1 — DRAM additive latency value in cycles for frequency set 1. Reset Source: ctl_amod_g_rst_n
  [14:8] PI_WRLAT_F1 — DRAM WRLAT value in cycles for frequency set 1. Reset Source: ctl_amod_g_rst_n
  [6:0] PI_CASLAT_LIN_F0 — Sets latency from read command sent to data received from/to controller for frequency set 0. Bit [0] is half-cycle increment and the upper bits define memory CAS latency for the controller. Reset Source: ctl_amod_g_rst_n
0x22E4 emif_ctlcfg_DENALI_PI_185
  [29:24] PI_ADDITIVE_LAT_F2 — DRAM additive latency value in cycles for frequency set 2. Reset Source: ctl_amod_g_rst_n
  [22:16] PI_WRLAT_F2 — DRAM WRLAT value in cycles for frequency set 2. Reset Source: ctl_amod_g_rst_n
  [14:8] PI_CASLAT_LIN_F1 — Sets latency from read command sent to data received from/to controller for frequency set 1. Bit [0] is half-cycle increment and the upper bits define memory CAS latency for the controller. Reset Source: ctl_amod_g_rst_n
  [7:0] PI_TPARITY_ERROR_CMD_INHIBIT_F1 — Defines the window after the PI receives a parity error during which DRAM commands will not execute for frequency set 1. Reset Source: ctl_amod_g_rst_n
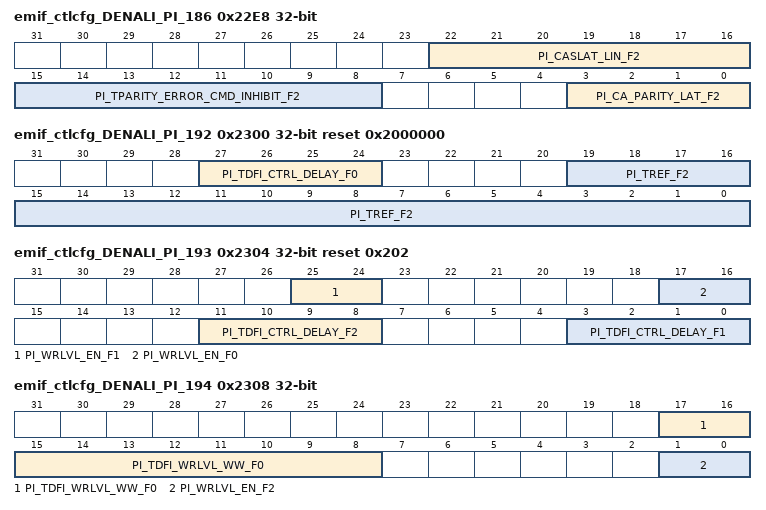
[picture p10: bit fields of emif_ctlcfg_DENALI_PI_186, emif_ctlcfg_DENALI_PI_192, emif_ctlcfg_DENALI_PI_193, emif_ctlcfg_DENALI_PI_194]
0x22E8 emif_ctlcfg_DENALI_PI_186
  [22:16] PI_CASLAT_LIN_F2 — Sets latency from read command sent to data received from/to controller for frequency set 2. Bit [0] is half-cycle increment and the upper bits define memory CAS latency for the controller. Reset Source: ctl_amod_g_rst_n
  [15:8] PI_TPARITY_ERROR_CMD_INHIBIT_F2 — Defines the window after the PI receives a parity error during which DRAM commands will not execute for frequency set 2. Reset Source: ctl_amod_g_rst_n
  [3:0] PI_CA_PARITY_LAT_F2 — DRAM CA parity latency value in cycles for frequency set 2. Reset Source: ctl_amod_g_rst_n
0x22EC emif_ctlcfg_DENALI_PI_187
  [9:0] PI_TRFC_F0 — DRAM tRFC value in memory clocks for frequency set 0. Reset Source: ctl_amod_g_rst_n
0x22F0 emif_ctlcfg_DENALI_PI_188
  [19:0] PI_TREF_F0 — DRAM tREF value in memory clocks for frequency set 0. Reset Source: ctl_amod_g_rst_n
0x22F4 emif_ctlcfg_DENALI_PI_189
  [9:0] PI_TRFC_F1 — DRAM tRFC value in memory clocks for frequency set 1. Reset Source: ctl_amod_g_rst_n
0x22F8 emif_ctlcfg_DENALI_PI_190
  [19:0] PI_TREF_F1 — DRAM tREF value in memory clocks for frequency set 1. Reset Source: ctl_amod_g_rst_n
0x22FC emif_ctlcfg_DENALI_PI_191
  [9:0] PI_TRFC_F2 — DRAM tRFC value in memory clocks for frequency set 2. Reset Source: ctl_amod_g_rst_n
0x2300 emif_ctlcfg_DENALI_PI_192 reset 0x2000000
  [27:24] PI_TDFI_CTRL_DELAY_F0 — Defines the DFI tCTRL_DELAY timing parameter [in DFI clocks] for frequency set 0, the delay between a DFI command change and a memory command. Reset Source: ctl_amod_g_rst_n
  [19:0] PI_TREF_F2 — DRAM tREF value in memory clocks for frequency set 2. Reset Source: ctl_amod_g_rst_n
0x2304 emif_ctlcfg_DENALI_PI_193 reset 0x202
  [25:24] PI_WRLVL_EN_F1 — Enable the PI write leveling module for frequency set 1. Bit[1] represents the support when non-initialization. Bit[0]represents the support when initialization. Set to 1 to enable. Reset Source: ctl_amod_g_rst_n
  [17:16] PI_WRLVL_EN_F0 — Enable the PI write leveling module for frequency set 0. Bit[1] represents the support when non-initialization. Bit[0]represents the support when initialization. Set to 1 to enable. Reset Source: ctl_amod_g_rst_n
  [11:8] PI_TDFI_CTRL_DELAY_F2 — Defines the DFI tCTRL_DELAY timing parameter [in DFI clocks] for frequency set 2, the delay between a DFI command change and a memory command. Reset Source: ctl_amod_g_rst_n
  [3:0] PI_TDFI_CTRL_DELAY_F1 — Defines the DFI tCTRL_DELAY timing parameter [in DFI clocks] for frequency set 1, the delay between a DFI command change and a memory command. Reset Source: ctl_amod_g_rst_n
0x2308 emif_ctlcfg_DENALI_PI_194
  [17:8] PI_TDFI_WRLVL_WW_F0 — Defines the DFI tWRLVL_WW timing parameter [in DFI clocks] for frequency set 0, the minimum cycles between dfi_wrlvl_strobe assertions. Reset Source: ctl_amod_g_rst_n
  [1:0] PI_WRLVL_EN_F2 — Enable the PI write leveling module for frequency set 2. Bit[1] represents the support when non-initialization. Bit[0]represents the support when initialization. Set to 1 to enable. Reset Source: ctl_amod_g_rst_n
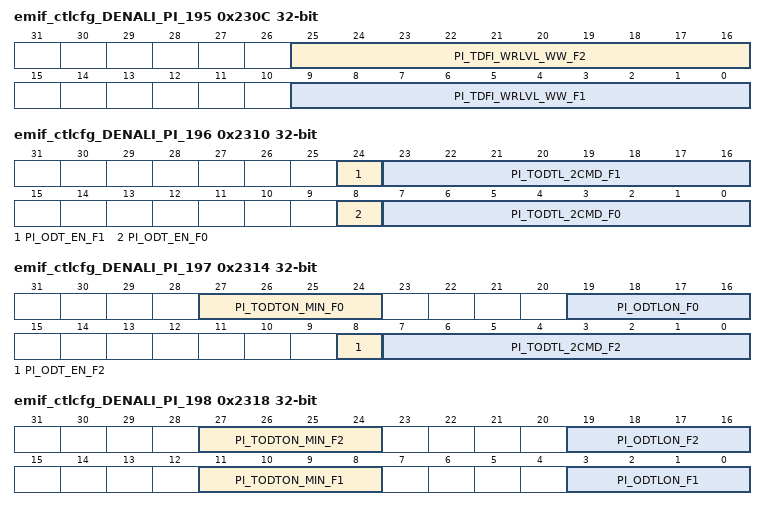
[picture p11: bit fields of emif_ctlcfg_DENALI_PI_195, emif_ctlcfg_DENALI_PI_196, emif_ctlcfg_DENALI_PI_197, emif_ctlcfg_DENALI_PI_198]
0x230C emif_ctlcfg_DENALI_PI_195
  [25:16] PI_TDFI_WRLVL_WW_F2 — Defines the DFI tWRLVL_WW timing parameter [in DFI clocks] for frequency set 2, the minimum cycles between dfi_wrlvl_strobe assertions. Reset Source: ctl_amod_g_rst_n
  [9:0] PI_TDFI_WRLVL_WW_F1 — Defines the DFI tWRLVL_WW timing parameter [in DFI clocks] for frequency set 1, the minimum cycles between dfi_wrlvl_strobe assertions. Reset Source: ctl_amod_g_rst_n
0x2310 emif_ctlcfg_DENALI_PI_196
  [24] PI_ODT_EN_F1 — Enable support of DRAM ODT. When enabled, PI will assert and de-assert ODT output to DRAM as needed for frequency set 1. Reset Source: ctl_amod_g_rst_n
  [23:16] PI_TODTL_2CMD_F1 — Defines the DRAM delay from an ODT de-assertion to the next non-write, non-read command for frequency set 1. Reset Source: ctl_amod_g_rst_n
  [8] PI_ODT_EN_F0 — Enable support of DRAM ODT. When enabled, PI will assert and de-assert ODT output to DRAM as needed for frequency set 0. Reset Source: ctl_amod_g_rst_n
  [7:0] PI_TODTL_2CMD_F0 — Defines the DRAM delay from an ODT de-assertion to the next non-write, non-read command for frequency set 0. Reset Source: ctl_amod_g_rst_n
0x2314 emif_ctlcfg_DENALI_PI_197
  [27:24] PI_TODTON_MIN_F0 — Defines the point in time when the device termination circuit leaves High-Z and ODT resistance begins to turn on for frequency set 0. Reset Source: ctl_amod_g_rst_n
  [19:16] PI_ODTLON_F0 — Defines the latency from a CAS-2 command to the tODTon reference for frequency set 0. Reset Source: ctl_amod_g_rst_n
  [8] PI_ODT_EN_F2 — Enable support of DRAM ODT. When enabled, PI will assert and de-assert ODT output to DRAM as needed for frequency set 2. Reset Source: ctl_amod_g_rst_n
  [7:0] PI_TODTL_2CMD_F2 — Defines the DRAM delay from an ODT de-assertion to the next non-write, non-read command for frequency set 2. Reset Source: ctl_amod_g_rst_n
0x2318 emif_ctlcfg_DENALI_PI_198
  [27:24] PI_TODTON_MIN_F2 — Defines the point in time when the device termination circuit leaves High-Z and ODT resistance begins to turn on for frequency set 2. Reset Source: ctl_amod_g_rst_n
  [19:16] PI_ODTLON_F2 — Defines the latency from a CAS-2 command to the tODTon reference for frequency set 2. Reset Source: ctl_amod_g_rst_n
  [11:8] PI_TODTON_MIN_F1 — Defines the point in time when the device termination circuit leaves High-Z and ODT resistance begins to turn on for frequency set 1. Reset Source: ctl_amod_g_rst_n
  [3:0] PI_ODTLON_F1 — Defines the latency from a CAS-2 command to the tODTon reference for frequency set 1. Reset Source: ctl_amod_g_rst_n
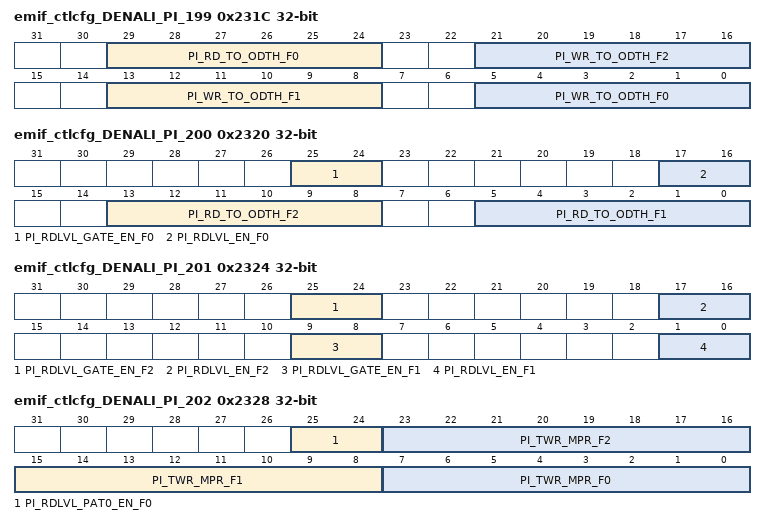
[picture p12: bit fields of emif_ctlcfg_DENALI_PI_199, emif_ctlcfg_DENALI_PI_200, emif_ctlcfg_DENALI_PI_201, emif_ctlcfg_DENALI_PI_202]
0x231C emif_ctlcfg_DENALI_PI_199
  [29:24] PI_RD_TO_ODTH_F0 — Defines the delay from a read command to ODT assertion for frequency set 0. Reset Source: ctl_amod_g_rst_n
  [21:16] PI_WR_TO_ODTH_F2 — Defines the delay from a write command to ODT assertion for frequency set 2. Reset Source: ctl_amod_g_rst_n
  [13:8] PI_WR_TO_ODTH_F1 — Defines the delay from a write command to ODT assertion for frequency set 1. Reset Source: ctl_amod_g_rst_n
  [5:0] PI_WR_TO_ODTH_F0 — Defines the delay from a write command to ODT assertion for frequency set 0. Reset Source: ctl_amod_g_rst_n
0x2320 emif_ctlcfg_DENALI_PI_200
  [25:24] PI_RDLVL_GATE_EN_F0 — Enable the PI gate training module for frequency set 0. Bit[1] represents the support when non-initialization. Bit[0]represents the support when initialization. Set to 1 to enable. Reset Source: ctl_amod_g_rst_n
  [17:16] PI_RDLVL_EN_F0 — Enable the PI data eye training module for frequency set 0. Bit[1] represents the support when non-initialization. Bit[0]represents the support when initialization. Set to 1 to enable. Reset Source: ctl_amod_g_rst_n
  [13:8] PI_RD_TO_ODTH_F2 — Defines the delay from a read command to ODT assertion for frequency set 2. Reset Source: ctl_amod_g_rst_n
  [5:0] PI_RD_TO_ODTH_F1 — Defines the delay from a read command to ODT assertion for frequency set 1. Reset Source: ctl_amod_g_rst_n
0x2324 emif_ctlcfg_DENALI_PI_201
  [25:24] PI_RDLVL_GATE_EN_F2 — Enable the PI gate training module for frequency set 2. Bit[1] represents the support when non-initialization. Bit[0]represents the support when initialization. Set to 1 to enable. Reset Source: ctl_amod_g_rst_n
  [17:16] PI_RDLVL_EN_F2 — Enable the PI data eye training module for frequency set 2. Bit[1] represents the support when non-initialization. Bit[0]represents the support when initialization. Set to 1 to enable. Reset Source: ctl_amod_g_rst_n
  [9:8] PI_RDLVL_GATE_EN_F1 — Enable the PI gate training module for frequency set 1. Bit[1] represents the support when non-initialization. Bit[0]represents the support when initialization. Set to 1 to enable. Reset Source: ctl_amod_g_rst_n
  [1:0] PI_RDLVL_EN_F1 — Enable the PI data eye training module for frequency set 1. Bit[1] represents the support when non-initialization. Bit[0]represents the support when initialization. Set to 1 to enable. Reset Source: ctl_amod_g_rst_n
0x2328 emif_ctlcfg_DENALI_PI_202
  [25:24] PI_RDLVL_PAT0_EN_F0 — Enable PATTERN-0 for read training for frequency set 0. bit1 for normal; bit0 for initialization. Reset Source: ctl_amod_g_rst_n
  [23:16] PI_TWR_MPR_F2 — Number of cycles after MPR write command and before any other command for frequency set 2. Reset Source: ctl_amod_g_rst_n
  [15:8] PI_TWR_MPR_F1 — Number of cycles after MPR write command and before any other command for frequency set 1. Reset Source: ctl_amod_g_rst_n
  [7:0] PI_TWR_MPR_F0 — Number of cycles after MPR write command and before any other command for frequency set 0. Reset Source: ctl_amod_g_rst_n
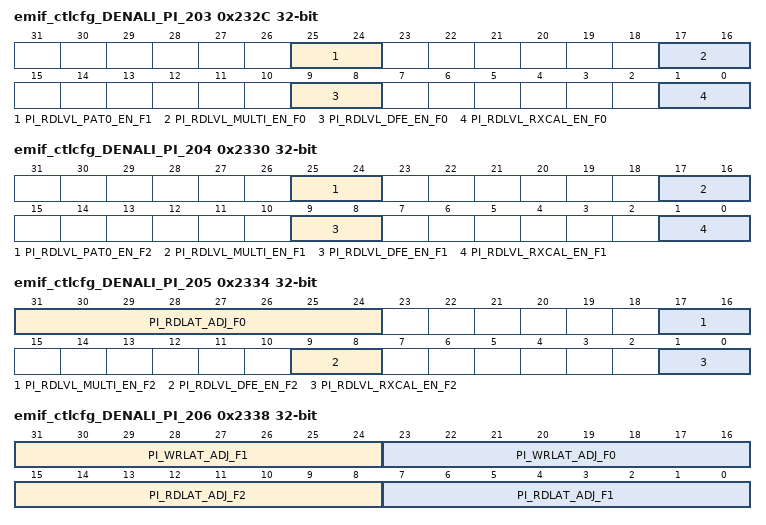
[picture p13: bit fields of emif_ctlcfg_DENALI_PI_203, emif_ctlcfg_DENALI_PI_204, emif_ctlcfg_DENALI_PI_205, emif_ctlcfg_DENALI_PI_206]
0x232C emif_ctlcfg_DENALI_PI_203
  [25:24] PI_RDLVL_PAT0_EN_F1 — Enable PATTERN-0 for read training for frequency set 1. bit1 for normal; bit0 for initialization. Reset Source: ctl_amod_g_rst_n
  [17:16] PI_RDLVL_MULTI_EN_F0 — Enable Multi-pattern [from PI_RDLVL_PATTERN_START, total PI_RDLVL_PATTERN_NUM] for read training for frequency set 0. bit1 for normal; bit0 for initialization. Reset Source: ctl_amod_g_rst_n
  [9:8] PI_RDLVL_DFE_EN_F0 — Enable DFE [PATTERN 8,9] for read training for frequency set 0. bit1 for normal; bit0 for initialization. Reset Source: ctl_amod_g_rst_n
  [1:0] PI_RDLVL_RXCAL_EN_F0 — Enable RX Offset calibration [PATTERN 14,15] for read training for frequency set 0. bit1 for normal; bit0 for initialization. Reset Source: ctl_amod_g_rst_n
0x2330 emif_ctlcfg_DENALI_PI_204
  [25:24] PI_RDLVL_PAT0_EN_F2 — Enable PATTERN-0 for read training for frequency set 2. bit1 for normal; bit0 for initialization. Reset Source: ctl_amod_g_rst_n
  [17:16] PI_RDLVL_MULTI_EN_F1 — Enable Multi-pattern [from PI_RDLVL_PATTERN_START, total PI_RDLVL_PATTERN_NUM] for read training for frequency set 1. bit1 for normal; bit0 for initialization. Reset Source: ctl_amod_g_rst_n
  [9:8] PI_RDLVL_DFE_EN_F1 — Enable DFE [PATTERN 8,9] for read training for frequency set 1. bit1 for normal; bit0 for initialization. Reset Source: ctl_amod_g_rst_n
  [1:0] PI_RDLVL_RXCAL_EN_F1 — Enable RX Offset calibration [PATTERN 14,15] for read training for frequency set 1. bit1 for normal; bit0 for initialization. Reset Source: ctl_amod_g_rst_n
0x2334 emif_ctlcfg_DENALI_PI_205
  [31:24] PI_RDLAT_ADJ_F0 — Adjusts the relative timing between DFI read commands and the dfi_rddata_en signal for frequency set 0. Reset Source: ctl_amod_g_rst_n
  [17:16] PI_RDLVL_MULTI_EN_F2 — Enable Multi-pattern [from PI_RDLVL_PATTERN_START, total PI_RDLVL_PATTERN_NUM] for read training for frequency set 2. bit1 for normal; bit0 for initialization. Reset Source: ctl_amod_g_rst_n
  [9:8] PI_RDLVL_DFE_EN_F2 — Enable DFE [PATTERN 8,9] for read training for frequency set 2. bit1 for normal; bit0 for initialization. Reset Source: ctl_amod_g_rst_n
  [1:0] PI_RDLVL_RXCAL_EN_F2 — Enable RX Offset calibration [PATTERN 14,15] for read training for frequency set 2. bit1 for normal; bit0 for initialization. Reset Source: ctl_amod_g_rst_n
0x2338 emif_ctlcfg_DENALI_PI_206
  [31:24] PI_WRLAT_ADJ_F1 — Adjusts the relative timing in memory clocks between DFI write commands and the dfi_wrdata_en signal for frequency set 1. Reset Source: ctl_amod_g_rst_n
  [23:16] PI_WRLAT_ADJ_F0 — Adjusts the relative timing in memory clocks between DFI write commands and the dfi_wrdata_en signal for frequency set 0. Reset Source: ctl_amod_g_rst_n
  [15:8] PI_RDLAT_ADJ_F2 — Adjusts the relative timing between DFI read commands and the dfi_rddata_en signal for frequency set 2. Reset Source: ctl_amod_g_rst_n
  [7:0] PI_RDLAT_ADJ_F1 — Adjusts the relative timing between DFI read commands and the dfi_rddata_en signal for frequency set 1. Reset Source: ctl_amod_g_rst_n
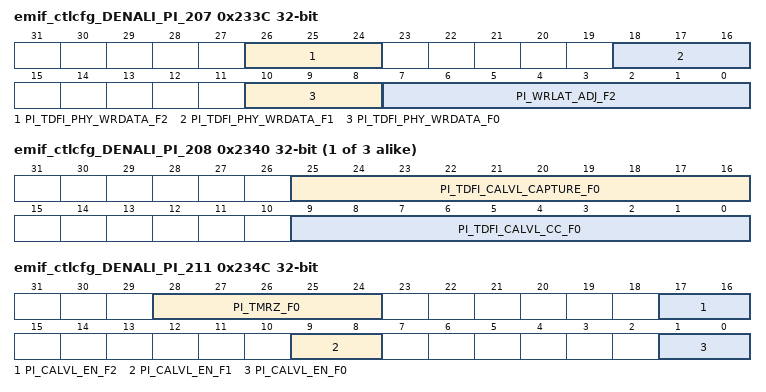
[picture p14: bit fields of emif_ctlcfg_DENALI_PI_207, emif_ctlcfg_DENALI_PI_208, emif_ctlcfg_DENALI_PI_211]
0x233C emif_ctlcfg_DENALI_PI_207
  [26:24] PI_TDFI_PHY_WRDATA_F2 — Defines the DFI tPHY_WRDATA timing parameter [in DFI PHY clocks] for frequency set 2, the maximum cycles between a dfi_wrdata_en assertion and a dfi_wrdata signal. Reset Source: ctl_amod_g_rst_n
  [18:16] PI_TDFI_PHY_WRDATA_F1 — Defines the DFI tPHY_WRDATA timing parameter [in DFI PHY clocks] for frequency set 1, the maximum cycles between a dfi_wrdata_en assertion and a dfi_wrdata signal. Reset Source: ctl_amod_g_rst_n
  [10:8] PI_TDFI_PHY_WRDATA_F0 — Defines the DFI tPHY_WRDATA timing parameter [in DFI PHY clocks] for frequency set 0, the maximum cycles between a dfi_wrdata_en assertion and a dfi_wrdata signal. Reset Source: ctl_amod_g_rst_n
  [7:0] PI_WRLAT_ADJ_F2 — Adjusts the relative timing in memory clocks between DFI write commands and the dfi_wrdata_en signal for frequency set 2. Reset Source: ctl_amod_g_rst_n
{0x2000+4i} emif_ctlcfg_DENALI_PI_{i} (i=208..210)
  [25:16] PI_TDFI_CALVL_CAPTURE_F{i-208} — Defines the DFI tCALVL_CAPTURE timing parameter [in DFI clocks] for frequency set {i-208}, the minimum cycles between a calibration command and a dfi_calvl_capture pulse. Reset Source: ctl_amod_g_rst_n
  [9:0] PI_TDFI_CALVL_CC_F{i-208} — Defines the DFI tCALVL_CC timing parameter [in DFI clocks] for frequency set {i-208}, the minimum cycles between calibration commands. Reset Source: ctl_amod_g_rst_n
0x234C emif_ctlcfg_DENALI_PI_211
  [28:24] PI_TMRZ_F0 — Defines the delay between a MRW CA exit command and the DQ tristate in memory clocks for frequency set 0. Reset Source: ctl_amod_g_rst_n
  [17:16] PI_CALVL_EN_F2 — Enable the PI CA training module. Bit[1] represents the support when non-initialization for frequency set 2. Bit[0]represents the support when initialization. Set to 1 to enable. Reset Source: ctl_amod_g_rst_n
  [9:8] PI_CALVL_EN_F1 — Enable the PI CA training module. Bit[1] represents the support when non-initialization for frequency set 1. Bit[0]represents the support when initialization. Set to 1 to enable. Reset Source: ctl_amod_g_rst_n
  [1:0] PI_CALVL_EN_F0 — Enable the PI CA training module. Bit[1] represents the support when non-initialization for frequency set 0. Bit[0]represents the support when initialization. Set to 1 to enable. Reset Source: ctl_amod_g_rst_n
